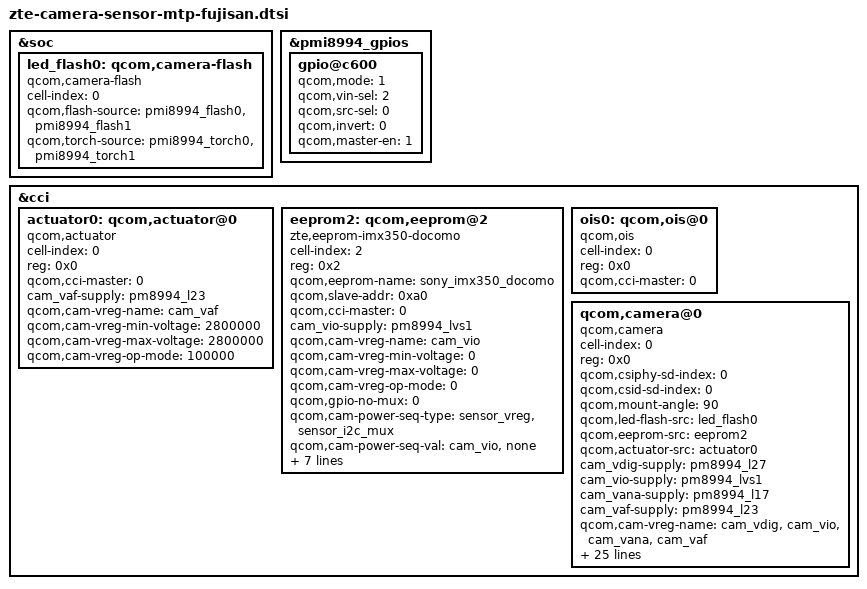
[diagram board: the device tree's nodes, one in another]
/*
 * Copyright (c) 2015 The Linux Foundation. All rights reserved.
 *
 * This program is free software; you can redistribute it and/or modify
 * it under the terms of the GNU General Public License version 2 and
 * only version 2 as published by the Free Software Foundation.
 *
 * This program is distributed in the hope that it will be useful,
 * but WITHOUT ANY WARRANTY; without even the implied warranty of
 * MERCHANTABILITY or FITNESS FOR A PARTICULAR PURPOSE.  See the
 * GNU General Public License for more details.
 */

&soc {
	led_flash0: qcom,camera-flash {
		cell-index = <0>;
		compatible = "qcom,camera-flash";
		qcom,flash-source = <&pmi8994_flash0 &pmi8994_flash1>;
		qcom,torch-source = <&pmi8994_torch0 &pmi8994_torch1>;
//		qcom,switch-source = <&pmi8994_switch>;
	};
};

&pmi8994_gpios {
	gpio@c600 {	/* GPIO 7, ois_en  */
		qcom,mode = <1>;
		qcom,vin-sel = <2>;
		qcom,src-sel = <0>;
		qcom,invert = <0>;   /* need invert = 0 */
		qcom,master-en = <1>;
		status = "okay";
	};
};

&cci {
	actuator0: qcom,actuator@0 {
		cell-index = <0>;
		reg = <0x0>;
		compatible = "qcom,actuator";
		qcom,cci-master = <0>;
		cam_vaf-supply = <&pm8994_l23>;
		qcom,cam-vreg-name = "cam_vaf";
		qcom,cam-vreg-min-voltage = <2800000>;
		qcom,cam-vreg-max-voltage = <2800000>;
		qcom,cam-vreg-op-mode = <100000>;
	};
	eeprom2: qcom,eeprom@2{
		compatible = "zte,eeprom-imx350-docomo";
		cell-index = <2>;
		reg = <0x2>;
		qcom,eeprom-name = "sony_imx350_docomo";
		qcom,slave-addr = <0xa0>;
		qcom,cci-master = <0>;
		cam_vio-supply = <&pm8994_lvs1>;
		qcom,cam-vreg-name =  "cam_vio";
		qcom,cam-vreg-min-voltage = <0>;
		qcom,cam-vreg-max-voltage = <0>;
		qcom,cam-vreg-op-mode = <0>;
		qcom,gpio-no-mux = <0>;
		pinctrl-names = "cam_default", "cam_suspend";
		qcom,cam-power-seq-type = "sensor_vreg",
								 "sensor_i2c_mux";
		qcom,cam-power-seq-val = "cam_vio",
								   "none";
		qcom,cam-power-seq-cfg-val = < 1 0>;
		qcom,cam-power-seq-delay =   < 3 0>;
		zte,num-blocks = <1>;
		zte,mem0    = <5372	 0x0000 2 0x0 1 0>;
		clocks = <&clock_mmss clk_mclk2_clk_src>,
			<&clock_mmss clk_camss_mclk2_clk>;
		clock-names = "cam_src_clk", "cam_clk";
		status = "ok";
		qcom,clock-rates = <19200000 0>;
	};
	ois0: qcom,ois@0 {
		cell-index = <0>;
		reg = <0x0>;
		compatible = "qcom,ois";
		qcom,cci-master = <0>;
//		qcom,platform-ois-en-gpio = <&pmi8994_gpios 7 0>; /* OIS_EN */
		status = "ok";
	};

	qcom,camera@0 {
		cell-index = <0>;
		compatible = "qcom,camera";
		reg = <0x0>;
		qcom,csiphy-sd-index = <0>;
		qcom,csid-sd-index = <0>;
		qcom,mount-angle = <90>;
		qcom,led-flash-src = <&led_flash0>;
		qcom,eeprom-src = <&eeprom2>;
		qcom,actuator-src = <&actuator0>;
		//qcom,ois-src = <&ois0>;
		cam_vdig-supply = <&pm8994_l27>;
		cam_vio-supply = <&pm8994_lvs1>;
		cam_vana-supply = <&pm8994_l17>;
		cam_vaf-supply = <&pm8994_l23>;
		qcom,cam-vreg-name = "cam_vdig", "cam_vio", "cam_vana","cam_vaf";
		qcom,cam-vreg-min-voltage = <1000000 0 3100000 2800000>;
		qcom,cam-vreg-max-voltage = <1000000 0 3100000 2800000>;
		qcom,cam-vreg-op-mode = <105000 0 80000 100000>;
		qcom,gpio-no-mux = <0>;
		pinctrl-names = "cam_default", "cam_suspend";
		pinctrl-0 = <&cam_sensor_mclk0_active &cam_sensor_rear_active>;
		pinctrl-1 = <&cam_sensor_mclk0_suspend &cam_sensor_rear_suspend>;
		gpios = <&tlmm 13 0>,
			<&tlmm 30 0>,
			<&tlmm 29 0>,
		       <&tlmm 38 0>;
		qcom,gpio-reset = <1>;
		qcom,gpio-standby = <2>;
		qcom,gpio-vdig = <3>;
		qcom,gpio-req-tbl-num = <0 1 2 3>;
		qcom,gpio-req-tbl-flags = <1 0 0 0>;
		qcom,gpio-req-tbl-label = "CAMIF_MCLK0",
					  "CAM_RESET0",
					  "CAM_STANDBY0",
					  "CAM_DVDD0";
		qcom,platform-ois-en-gpio = <&pmi8994_gpios 7 0>; /* OIS_EN */
		qcom,sensor-position = <0>;
		qcom,sensor-mode = <0>;
		qcom,cci-master = <0>;
		status = "ok";
		clocks = <&clock_mmss clk_mclk0_clk_src>,
				<&clock_mmss clk_camss_mclk0_clk>;
		clock-names = "cam_src_clk", "cam_clk";
		qcom,clock-rates = <24000000 0>;
	};
};
